# ioADuCM302x register map
Registers are 16-bit, access not given, no defined reset value unless marked. A register's access mark holds for its fields unless they carry their own. Addresses are absolute; registers are grouped by the start of their names; [hi:lo] are bit positions; {n}, {i} and the like mark numbered series.

## BEEP0
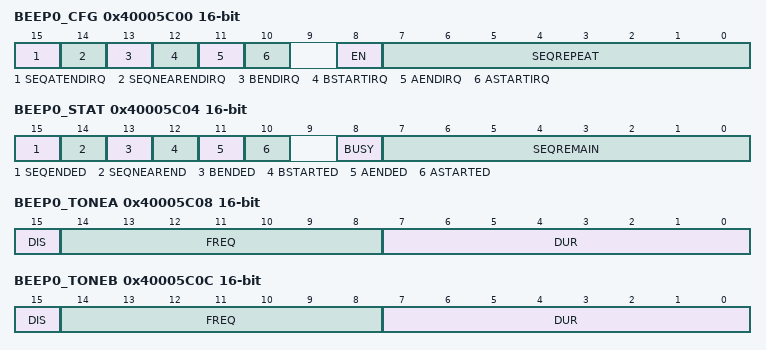
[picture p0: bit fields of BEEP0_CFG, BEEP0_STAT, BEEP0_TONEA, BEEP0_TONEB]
0x40005C00 BEEP0_CFG
  [15] SEQATENDIRQ, [14] SEQNEARENDIRQ, [13] BENDIRQ, [12] BSTARTIRQ, [11] AENDIRQ, [10] ASTARTIRQ, [8] EN, [7:0] SEQREPEAT
0x40005C04 BEEP0_STAT
  [15] SEQENDED, [14] SEQNEAREND, [13] BENDED, [12] BSTARTED, [11] AENDED, [10] ASTARTED, [8] BUSY, [7:0] SEQREMAIN
0x40005C08 BEEP0_TONEA
  [15] DIS, [14:8] FREQ, [7:0] DUR
0x40005C0C BEEP0_TONEB
  [15] DIS, [14:8] FREQ, [7:0] DUR

## ADC0
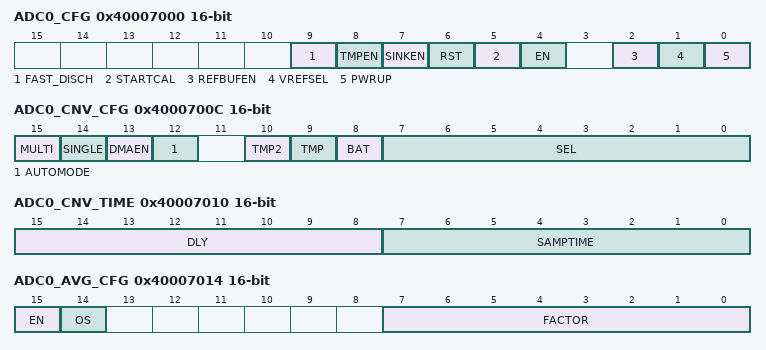
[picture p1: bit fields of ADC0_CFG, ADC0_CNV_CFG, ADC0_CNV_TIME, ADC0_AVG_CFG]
0x40007000 ADC0_CFG
  [9] FAST_DISCH, [8] TMPEN, [7] SINKEN, [6] RST, [5] STARTCAL, [4] EN, [2] REFBUFEN, [1] VREFSEL, [0] PWRUP
0x40007004 ADC0_PWRUP
  [9:0] WAIT
0x40007008 ADC0_CAL_WORD
  [6:0] VALUE
0x4000700C ADC0_CNV_CFG
  [15] MULTI, [14] SINGLE, [13] DMAEN, [12] AUTOMODE, [10] TMP2, [9] TMP, [8] BAT, [7:0] SEL
0x40007010 ADC0_CNV_TIME
  [15:8] DLY, [7:0] SAMPTIME
0x40007014 ADC0_AVG_CFG
  [15] EN, [14] OS, [7:0] FACTOR
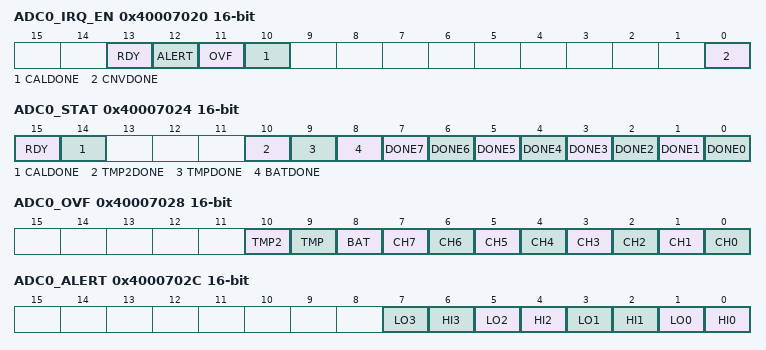
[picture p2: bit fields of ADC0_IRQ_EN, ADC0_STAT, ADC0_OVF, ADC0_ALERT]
0x40007020 ADC0_IRQ_EN
  [13] RDY, [12] ALERT, [11] OVF, [10] CALDONE, [0] CNVDONE
0x40007024 ADC0_STAT
  [15] RDY, [14] CALDONE, [10] TMP2DONE, [9] TMPDONE, [8] BATDONE, [n] DONE{n} (n=0..7)
0x40007028 ADC0_OVF
  [10] TMP2, [9] TMP, [8] BAT, [n] CH{n} (n=0..7)
0x4000702C ADC0_ALERT
  [2n+1] LO{n} (n=0..3), [2n] HI{n} (n=0..3)
{0x40007030+4i} ADC0_CH{i}_OUT (i=0..7)
0x40007050 ADC0_BAT_OUT
0x40007054 ADC0_TMP_OUT
0x40007058 ADC0_TMP2_OUT
0x4000705C ADC0_DMA_OUT
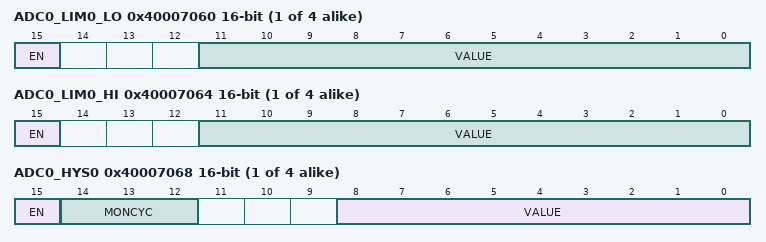
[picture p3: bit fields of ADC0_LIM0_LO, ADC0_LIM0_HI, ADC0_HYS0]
{0x40007060+0x10*i} ADC0_LIM{i}_LO (i=0..3)
  [15] EN, [11:0] VALUE
{0x40007064+0x10*i} ADC0_LIM{i}_HI (i=0..3)
  [15] EN, [11:0] VALUE
{0x40007068+0x10*i} ADC0_HYS{i} (i=0..3)
  [15] EN, [14:12] MONCYC, [8:0] VALUE
0x400070C0 ADC0_CFG1
  [0] RBUFLP

## DMA0
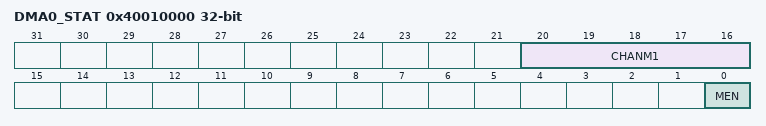
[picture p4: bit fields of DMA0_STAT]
0x40010000 DMA0_STAT 32-bit
  [20:16] CHANM1, [0] MEN
0x40010004 DMA0_CFG 32-bit
  [0] MEN
0x40010008 DMA0_PDBPTR 32-bit
0x4001000C DMA0_ADBPTR 32-bit
0x40010014 DMA0_SWREQ 32-bit
  [24:0] CHAN
0x40010020 DMA0_RMSK_SET 32-bit
  [24:0] CHAN
0x40010024 DMA0_RMSK_CLR 32-bit
  [24:0] CHAN
0x40010028 DMA0_EN_SET 32-bit
  [24:0] CHAN
0x4001002C DMA0_EN_CLR 32-bit
  [24:0] CHAN
0x40010030 DMA0_ALT_SET 32-bit
  [24:0] CHAN
0x40010034 DMA0_ALT_CLR 32-bit
  [24:0] CHAN
0x40010038 DMA0_PRI_SET 32-bit
  [24:0] CHAN
0x4001003C DMA0_PRI_CLR 32-bit
  [24:0] CHPRICLR
0x40010048 DMA0_ERRCHNL_CLR 32-bit
  [24:0] CHAN
0x4001004C DMA0_ERR_CLR 32-bit
  [24:0] CHAN
0x40010050 DMA0_INVALIDDESC_CLR 32-bit
  [24:0] CHAN
0x40010800 DMA0_BS_SET 32-bit
  [24:0] CHAN
0x40010804 DMA0_BS_CLR 32-bit
  [24:0] CHAN
0x40010810 DMA0_SRCADDR_SET 32-bit
  [24:0] CHAN
0x40010814 DMA0_SRCADDR_CLR 32-bit
  [24:0] CHAN
0x40010818 DMA0_DSTADDR_SET 32-bit
  [24:0] CHAN
0x4001081C DMA0_DSTADDR_CLR 32-bit
  [24:0] CHAN
0x40010FE0 DMA0_REVID 32-bit
  [7:0] VALUE

## FLCC0
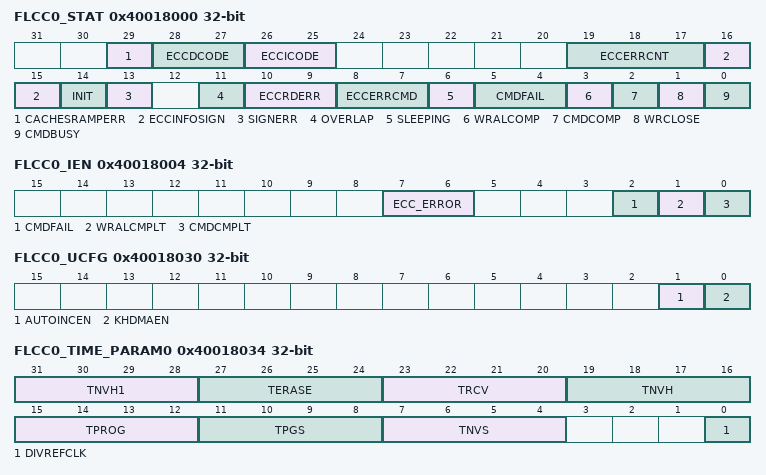
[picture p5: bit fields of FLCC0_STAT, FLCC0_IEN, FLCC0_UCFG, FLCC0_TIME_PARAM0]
0x40018000 FLCC0_STAT 32-bit
  [29] CACHESRAMPERR, [28:27] ECCDCODE, [26:25] ECCICODE, [19:17] ECCERRCNT, [16:15] ECCINFOSIGN, [14] INIT, [13] SIGNERR, [11] OVERLAP, [10:9] ECCRDERR, [8:7] ECCERRCMD, [6] SLEEPING, [5:4] CMDFAIL, [3] WRALCOMP, [2] CMDCOMP, [1] WRCLOSE, [0] CMDBUSY
0x40018004 FLCC0_IEN 32-bit
  [7:6] ECC_ERROR, [2] CMDFAIL, [1] WRALCMPLT, [0] CMDCMPLT
0x40018008 FLCC0_CMD 32-bit
  [3:0] VALUE
0x4001800C FLCC0_KH_ADDR 32-bit
  [18:3] VALUE
0x40018010 FLCC0_KH_DATA0 32-bit
0x40018014 FLCC0_KH_DATA1 32-bit
0x40018018 FLCC0_PAGE_ADDR0 32-bit
  [18:10] VALUE
0x4001801C FLCC0_PAGE_ADDR1 32-bit
  [18:10] VALUE
0x40018020 FLCC0_KEY 32-bit
0x40018024 FLCC0_WR_ABORT_ADDR 32-bit
0x40018028 FLCC0_WRPROT 32-bit
0x4001802C FLCC0_SIGNATURE 32-bit
0x40018030 FLCC0_UCFG 32-bit
  [1] AUTOINCEN, [0] KHDMAEN
0x40018034 FLCC0_TIME_PARAM0 32-bit
  [31:28] TNVH1, [27:24] TERASE, [23:20] TRCV, [19:16] TNVH, [15:12] TPROG, [11:8] TPGS, [7:4] TNVS, [0] DIVREFCLK
0x40018038 FLCC0_TIME_PARAM1 32-bit
  [3:0] TWK
0x4001803C FLCC0_ABORT_EN_LO 32-bit
0x40018040 FLCC0_ABORT_EN_HI 32-bit
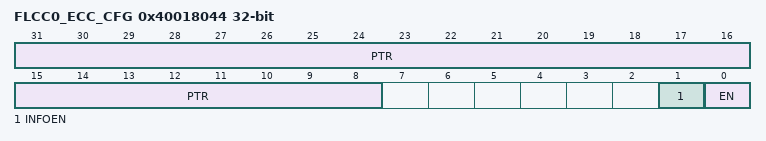
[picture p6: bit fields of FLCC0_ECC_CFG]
0x40018044 FLCC0_ECC_CFG 32-bit
  [31:8] PTR, [1] INFOEN, [0] EN
0x40018048 FLCC0_ECC_ADDR 32-bit
  [18:0] VALUE
0x40018050 FLCC0_POR_SEC 32-bit
  [0] SECURE
0x40018054 FLCC0_VOL_CFG 32-bit
  [0] INFO_REMAP
0x40018058 FLCC0_CACHE_STAT 32-bit
  [0] ICEN
0x4001805C FLCC0_CACHE_SETUP 32-bit
  [0] ICEN
0x40018060 FLCC0_CACHE_KEY 32-bit
